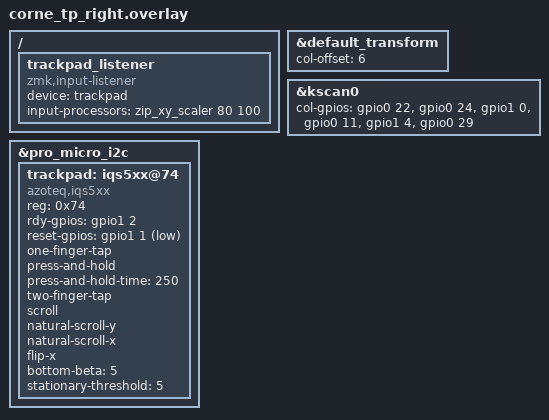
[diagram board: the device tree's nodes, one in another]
/*
 * Copyright (c) 2020 ZMK Contributors
 *
 * SPDX-License-Identifier: MIT
 */

#include "corne_tp.dtsi"

&default_transform {
    col-offset = <6>;
};

&kscan0 {
    col-gpios
        = <&gpio0 22 GPIO_ACTIVE_HIGH>
        , <&gpio0 24 GPIO_ACTIVE_HIGH>
        , <&gpio1 0  GPIO_ACTIVE_HIGH>
        , <&gpio0 11 GPIO_ACTIVE_HIGH>
        , <&gpio1 4  GPIO_ACTIVE_HIGH>
        , <&gpio0 29 GPIO_ACTIVE_HIGH>
        ;
};

&pro_micro_i2c {
    status = "okay";

    trackpad: iqs5xx@74 {
        compatible = "azoteq,iqs5xx";
        reg = <0x74>;
        status = "okay";

        rdy-gpios   = <&gpio1 2 GPIO_ACTIVE_HIGH>;
        reset-gpios = <&gpio1 1 GPIO_ACTIVE_LOW>;

        one-finger-tap;
        press-and-hold;
        press-and-hold-time = <250>;
        two-finger-tap;

        scroll;
        natural-scroll-y;
        natural-scroll-x;

        flip-x;

        bottom-beta = <5>;
        stationary-threshold = <5>;
    };
};

#include <input/processors.dtsi>

/ {
    trackpad_listener {
        compatible = "zmk,input-listener";
        device = <&trackpad>;
        input-processors = <&zip_xy_scaler 80 100>;
    };
};
